# STM32L4x2 register map
File version: 2.3
CPU: CM4 r0p1, little endian, MPU, FPU, 4 interrupt priority bits
Registers are 32-bit, read-write, reset 0x0 unless marked. A register's access mark holds for its fields unless they carry their own. Offsets are from the block's base; [hi:lo] are bit positions; 'fields as' and 'values as' point back to an identical list.

## COMP — Comparator
Base 0x40010200
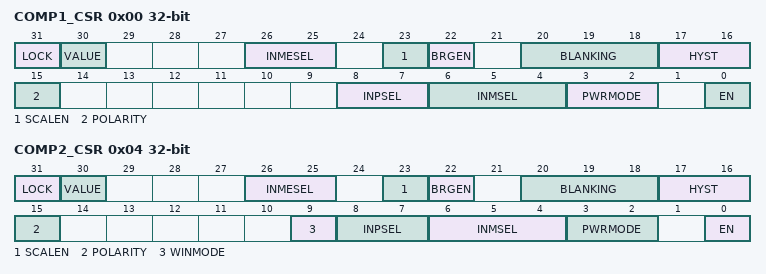
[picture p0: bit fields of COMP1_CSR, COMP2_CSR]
0x00 COMP1_CSR access per field — Comparator 1 control and status register
  [31] LOCK wo — COMP1_CSR register lock bit
    0=Unlocked (Comparator CSR bits are read-write); 1=Locked (Comparator CSR bits are read-only)
  [30] VALUE ro — Comparator 1 output status bit
    0=Low (Comparator output is low); 1=High (Comparator output is high)
  [26:25] INMESEL rw — comparator 1 input minus extended selection bits
    0=PC4; 1=PA0; 2=PA4; 3=PA5
  [23] SCALEN rw — Voltage scaler enable bit
    0=Disabled (Voltage scaler disabled); 1=Enabled (Voltage scaler enabled)
  [22] BRGEN rw — Scaler bridge enable
    0=Disabled (Scaler resistor bridge disabled); 1=Enabled (Scaler resistor bridge enabled)
  [20:18] BLANKING rw — Comparator 1 blanking source selection bits
    0=NoBlanking; 4=TIM1OC5 (TIM15 OC1 selected as blanking source)
  [17:16] HYST rw — Comparator 1 hysteresis selection bits
    0=None (No hysteresis); 1=Low (Low hysteresis); 2=Medium hysteresis; 3=High hysteresis
  [15] POLARITY rw — Comparator 1 polarity selection bit
    0=Normal (Comparator X output value not inverted); 1=Inverted (Comparator X output value inverted)
  [8:7] INPSEL rw — Comparator1 input plus selection bit
    0=PC5 (PC5 connected to input plus); 1=PB2 (PB2 connected to input plus); 2=PA3 (PA3 connected to input plus)
  [6:4] INMSEL rw — Comparator 1 Input Minus connection configuration bit
    0=OneQuarterVRef (1/4 of VRefint); 1=OneHalfVRef (1/2 of VRefint); 2=ThreeQuarterVRef (3/4 of VRefint); 3=VRefint; 4=DAC_CH1 (DAC Channel 1); 5=DAC_CH2 (DAC Channel 2); 6=PB1; 7=Extended (GPIO selected with INMESEL)
  [3:2] PWRMODE rw — Power Mode of the comparator 1
    0=High speed / full power; 1=Medium speed / medium power; 3=Low speed / ultra-low power
  [0] EN rw — Comparator 1 enable bit
    0=Disabled (Comparator X disabled); 1=Enabled (Comparator X enabled)
0x04 COMP2_CSR access per field — Comparator 2 control and status register
  [31] LOCK wo — COMP2_CSR register lock bit
    values as COMP1_CSR.LOCK
  [30] VALUE ro — Comparator 2 output status bit
    values as COMP1_CSR.VALUE
  [26:25] INMESEL rw — comparator 2 input minus extended selection bits
    0=PB7; 1=PA2; 2=PA4; 3=PA5
  [23] SCALEN rw — Voltage scaler enable bit
    values as COMP1_CSR.SCALEN
  [22] BRGEN rw — Scaler bridge enable
    values as COMP1_CSR.BRGEN
  [20:18] BLANKING rw — Comparator 2 blanking source selection bits
    values as COMP1_CSR.BLANKING
  [17:16] HYST rw — Comparator 2 hysteresis selection bits
    values as COMP1_CSR.HYST
  [15] POLARITY rw — Comparator 2 polarity selection bit
    values as COMP1_CSR.POLARITY
  [9] WINMODE rw — Windows mode selection bit
    0=Disabled (COMP2 input plus is not connected to COMP1); 1=Enabled (COMP2 input plus is connected to COMP1)
  [8:7] INPSEL rw — Comparator 2 Input Plus connection configuration bit
    0=PB4 (PB4 connected to input plus); 1=PB6 (PB6 connected to input plus); 2=PA3 (PA3 connected to input plus)
  [6:4] INMSEL rw — Comparator 2 Input Minus connection configuration bit
    0=OneQuarterVRef (1/4 of VRefint); 1=OneHalfVRef (1/2 of VRefint); 2=ThreeQuarterVRef (3/4 of VRefint); 3=VRefint; 4=DAC_CH1 (DAC Channel 1); 5=DAC_CH2 (DAC Channel 2); 6=PB3; 7=Extended (GPIO selected by INMESEL)
  [3:2] PWRMODE rw — Power Mode of the comparator 2
    values as COMP1_CSR.PWRMODE
  [0] EN rw — Comparator 2 enable bit
    values as COMP1_CSR.EN

## FIREWALL
Base 0x40011C00
0x00 CSSA — Code segment start address
  [23:8] ADD — code segment start address
0x04 CSL — Code segment length
  [21:8] LENG — code segment length
0x08 NVDSSA — Non-volatile data segment start address
  [23:8] ADD
0x0C NVDSL — Non-volatile data segment length
  [21:8] LENG
0x10 VDSSA — Volatile data segment start address
  [15:6] ADD
0x14 VDSL — Volatile data segment length
  [15:6] LENG — Non-volatile data segment length
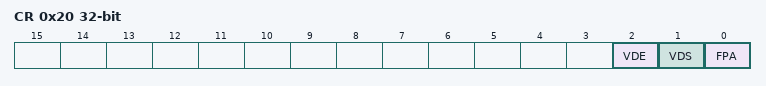
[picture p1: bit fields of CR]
0x20 CR — Configuration register
  [2] VDE — Volatile data execution
    on read: 0=NotExecutable (Volatile data segment cannot be executed if VDS = 0); 1=Executable (Volatile data segment is declared executable whatever VDS bit value) | on write: 0=Resets volatile data execution bit
  [1] VDS — Volatile data shared
    on read: 0=NotShared (Volatile data segment is not shared and cannot be hit by a non protected executable code when the Firewall is closed); 1=Shared (Volatile data segment is shared with non protected application code) | on write: 0=Resets volatile data shared bit
  [0] FPA — Firewall pre alarm
    on write: 0=PreArmReset (Any code executed outside the protected segment when the Firewall is opened will generate a system reset); 1=PreArmSet (Any code executed outside the protected segment will close the Firewall)
